# ATSAM4E16CB device description
Architecture: CORTEX-M4; Family: SAM4; Series: SAM4E
Registers are 32-bit, read-write, no defined reset value unless marked. A register's access mark holds for its fields unless they carry their own. Offsets are from the block's base; [hi:lo] are bit positions; {n}, {i} and the like mark numbered series.

## PIO — Parallel Input/Output Controller
Instances: PIOA 0x400E0E00, PIOB 0x400E1000, PIOC 0x400E1200
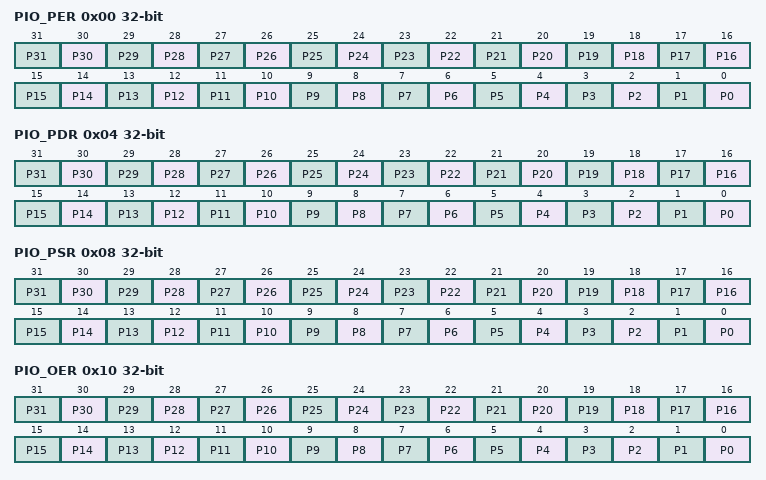
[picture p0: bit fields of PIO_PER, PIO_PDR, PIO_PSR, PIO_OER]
0x00 PIO_PER wo — PIO Enable Register
  [n] P{n} (n=0..31) — PIO Enable
0x04 PIO_PDR wo — PIO Disable Register
  [n] P{n} (n=0..31) — PIO Disable
0x08 PIO_PSR ro — PIO Status Register
  [n] P{n} (n=0..31) — PIO Status
0x10 PIO_OER wo — Output Enable Register
  [n] P{n} (n=0..31) — Output Enable
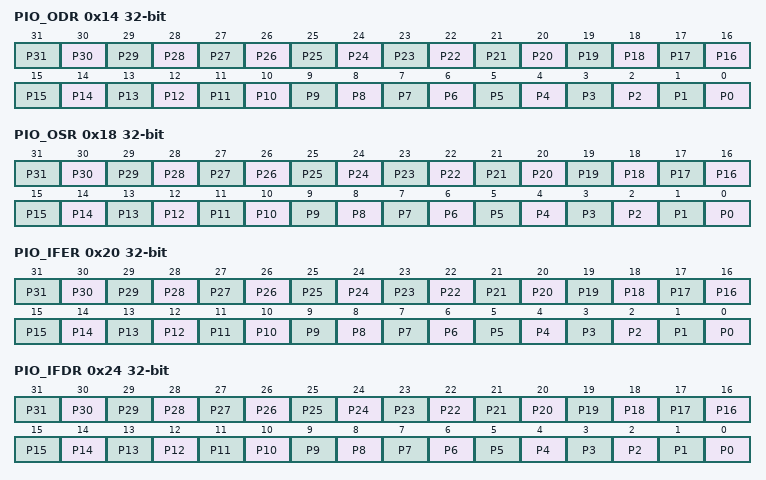
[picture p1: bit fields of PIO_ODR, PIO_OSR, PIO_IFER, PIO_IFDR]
0x14 PIO_ODR wo — Output Disable Register
  [n] P{n} (n=0..31) — Output Disable
0x18 PIO_OSR ro — Output Status Register
  [n] P{n} (n=0..31) — Output Status
0x20 PIO_IFER wo — Glitch Input Filter Enable Register
  [n] P{n} (n=0..31) — Input Filter Enable
0x24 PIO_IFDR wo — Glitch Input Filter Disable Register
  [n] P{n} (n=0..31) — Input Filter Disable
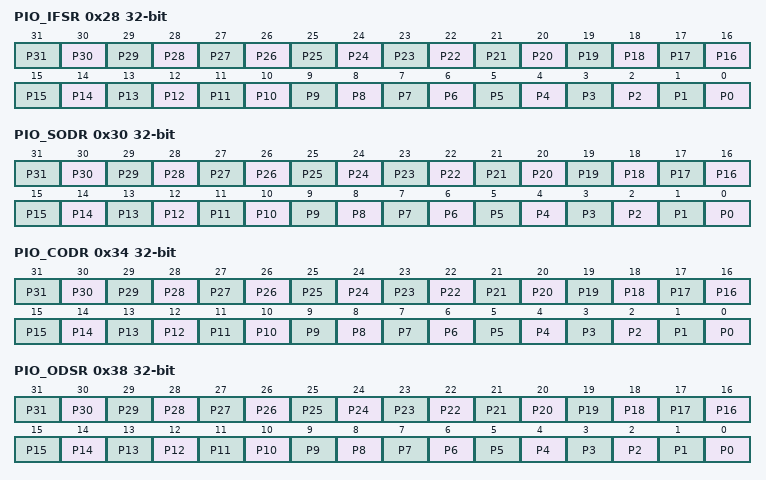
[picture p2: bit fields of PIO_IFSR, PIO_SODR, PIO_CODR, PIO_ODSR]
0x28 PIO_IFSR ro — Glitch Input Filter Status Register
  [n] P{n} (n=0..31) — Input Filer Status
0x30 PIO_SODR wo — Set Output Data Register
  [n] P{n} (n=0..31) — Set Output Data
0x34 PIO_CODR wo — Clear Output Data Register
  [n] P{n} (n=0..31) — Clear Output Data
0x38 PIO_ODSR — Output Data Status Register
  [n] P{n} (n=0..31) — Output Data Status
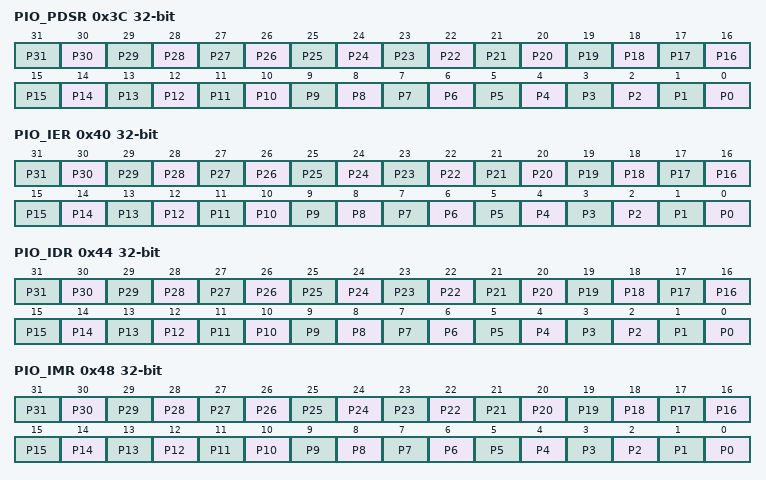
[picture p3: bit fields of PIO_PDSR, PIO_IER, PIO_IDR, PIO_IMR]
0x3C PIO_PDSR ro — Pin Data Status Register
  [n] P{n} (n=0..31) — Output Data Status
0x40 PIO_IER wo — Interrupt Enable Register
  [n] P{n} (n=0..31) — Input Change Interrupt Enable
0x44 PIO_IDR wo — Interrupt Disable Register
  [n] P{n} (n=0..31) — Input Change Interrupt Disable
0x48 PIO_IMR ro — Interrupt Mask Register
  [n] P{n} (n=0..31) — Input Change Interrupt Mask
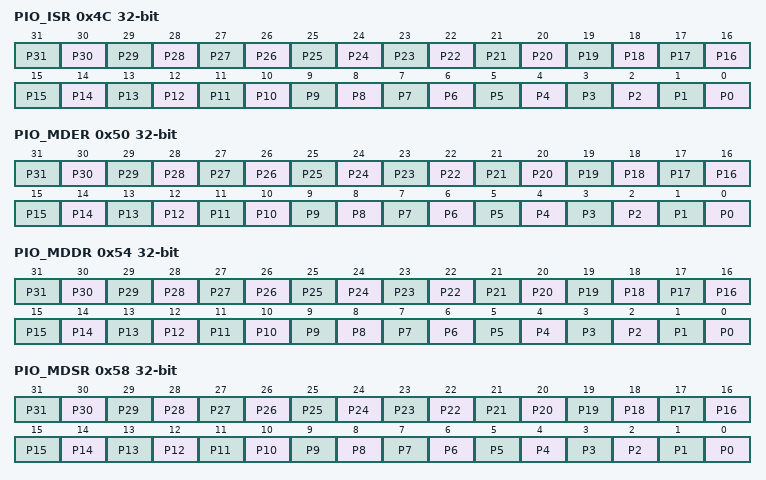
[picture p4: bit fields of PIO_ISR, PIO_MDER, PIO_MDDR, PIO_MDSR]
0x4C PIO_ISR ro — Interrupt Status Register
  [n] P{n} (n=0..31) — Input Change Interrupt Status
0x50 PIO_MDER wo — Multi-driver Enable Register
  [n] P{n} (n=0..31) — Multi-drive Enable
0x54 PIO_MDDR wo — Multi-driver Disable Register
  [n] P{n} (n=0..31) — Multi-drive Disable
0x58 PIO_MDSR ro — Multi-driver Status Register
  [n] P{n} (n=0..31) — Multi-drive Status
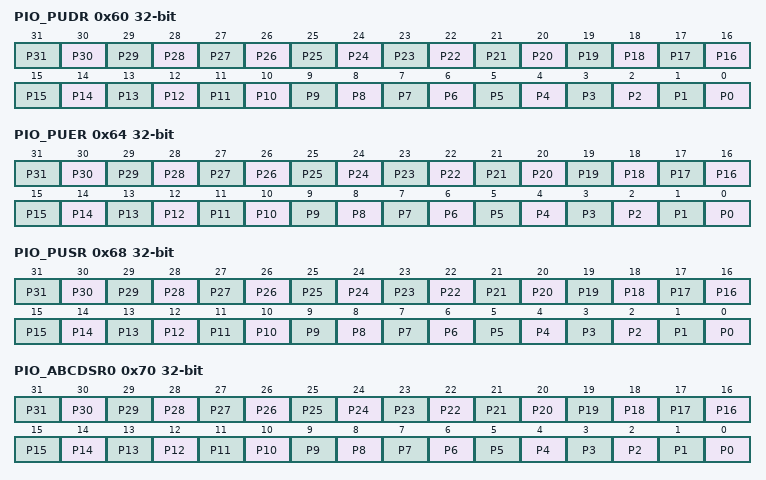
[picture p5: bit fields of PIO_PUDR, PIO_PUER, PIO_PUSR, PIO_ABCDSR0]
0x60 PIO_PUDR wo — Pull-up Disable Register
  [n] P{n} (n=0..31) — Pull-Up Disable
0x64 PIO_PUER wo — Pull-up Enable Register
  [n] P{n} (n=0..31) — Pull-Up Enable
0x68 PIO_PUSR ro — Pad Pull-up Status Register
  [n] P{n} (n=0..31) — Pull-Up Status
0x70 PIO_ABCDSR0 — Peripheral Select Register 0
  [n] P{n} (n=0..31) — Peripheral Select
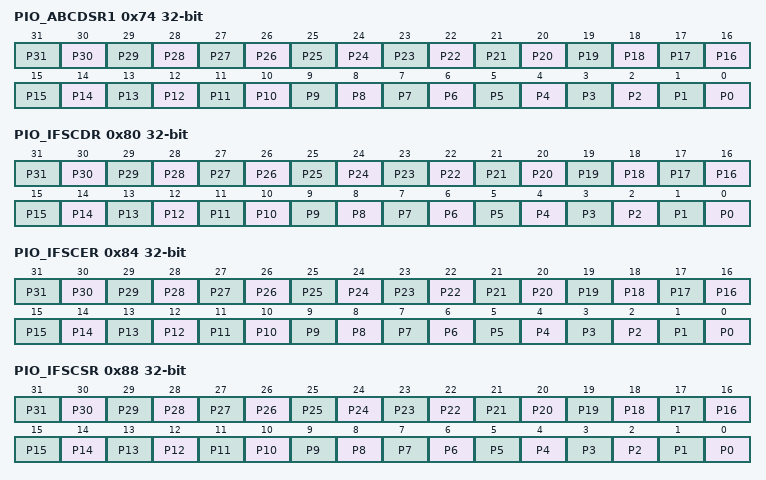
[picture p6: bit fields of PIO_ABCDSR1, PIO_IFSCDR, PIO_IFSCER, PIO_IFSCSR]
0x74 PIO_ABCDSR1 — Peripheral Select Register 1
  [n] P{n} (n=0..31) — Peripheral Select
0x80 PIO_IFSCDR wo — Input Filter Slow Clock Disable Register
  [n] P{n} (n=0..31) — Peripheral Clock Glitch Filtering Select
0x84 PIO_IFSCER wo — Input Filter Slow Clock Enable Register
  [n] P{n} (n=0..31) — Slow Clock Debouncing Filtering Select
0x88 PIO_IFSCSR ro — Input Filter Slow Clock Status Register
  [n] P{n} (n=0..31) — Glitch or Debouncing Filter Selection Status
0x8C PIO_SCDR — Slow Clock Divider Debouncing Register
  [13:0] DIV — Slow Clock Divider Selection for Debouncing
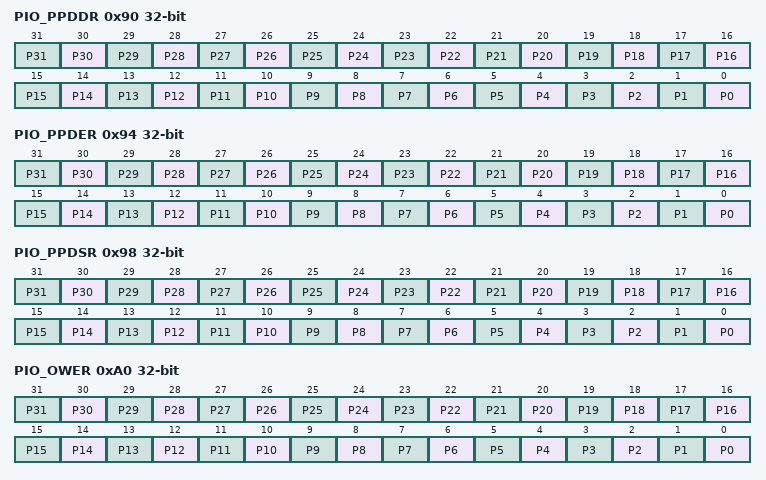
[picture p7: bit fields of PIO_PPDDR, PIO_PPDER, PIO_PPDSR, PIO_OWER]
0x90 PIO_PPDDR wo — Pad Pull-down Disable Register
  [n] P{n} (n=0..31) — Pull-Down Disable
0x94 PIO_PPDER wo — Pad Pull-down Enable Register
  [n] P{n} (n=0..31) — Pull-Down Enable
0x98 PIO_PPDSR ro — Pad Pull-down Status Register
  [n] P{n} (n=0..31) — Pull-Down Status
0xA0 PIO_OWER wo — Output Write Enable
  [n] P{n} (n=0..31) — Output Write Enable
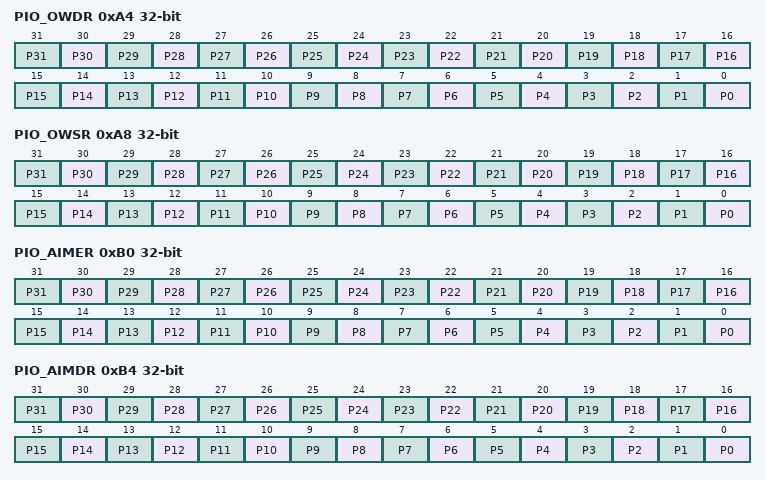
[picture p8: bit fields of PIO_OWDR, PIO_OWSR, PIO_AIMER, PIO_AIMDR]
0xA4 PIO_OWDR wo — Output Write Disable
  [n] P{n} (n=0..31) — Output Write Disable
0xA8 PIO_OWSR ro — Output Write Status Register
  [n] P{n} (n=0..31) — Output Write Status
0xB0 PIO_AIMER wo — Additional Interrupt Modes Enable Register
  [n] P{n} (n=0..31) — Additional Interrupt Modes Enable
0xB4 PIO_AIMDR wo — Additional Interrupt Modes Disable Register
  [n] P{n} (n=0..31) — Additional Interrupt Modes Disable
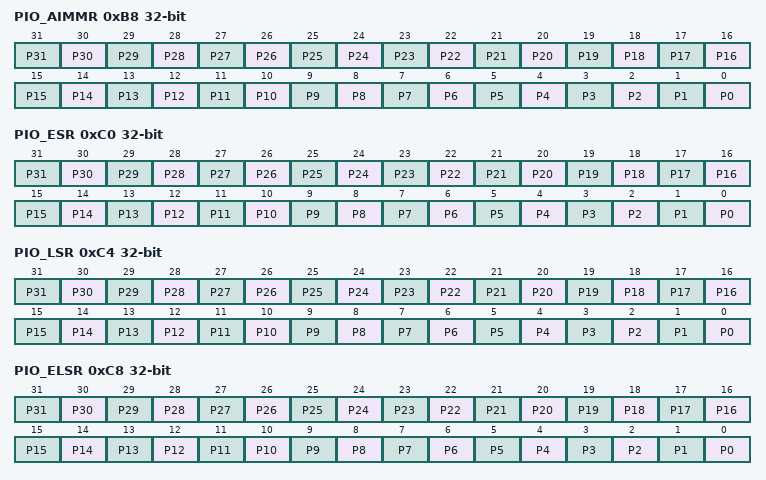
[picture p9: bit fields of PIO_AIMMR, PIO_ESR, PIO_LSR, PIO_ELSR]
0xB8 PIO_AIMMR ro — Additional Interrupt Modes Mask Register
  [n] P{n} (n=0..31) — Peripheral CD Status
0xC0 PIO_ESR wo — Edge Select Register
  [n] P{n} (n=0..31) — Edge Interrupt Selection
0xC4 PIO_LSR wo — Level Select Register
  [n] P{n} (n=0..31) — Level Interrupt Selection
0xC8 PIO_ELSR ro — Edge/Level Status Register
  [n] P{n} (n=0..31) — Edge/Level Interrupt Source Selection
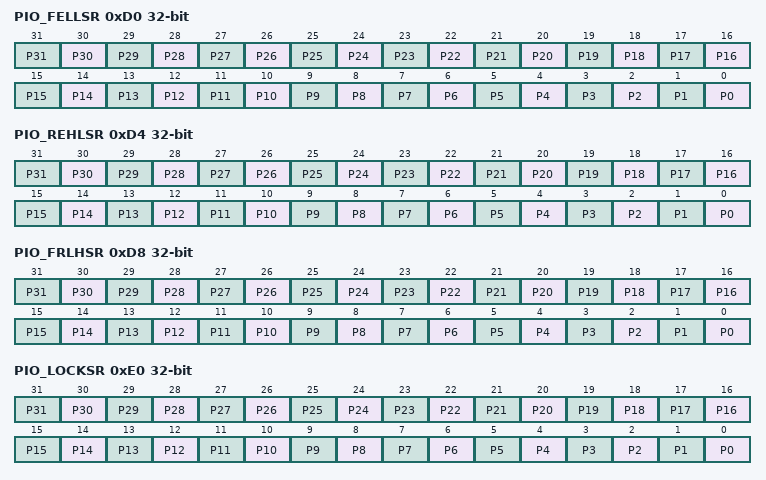
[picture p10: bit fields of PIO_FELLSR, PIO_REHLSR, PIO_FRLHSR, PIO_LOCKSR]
0xD0 PIO_FELLSR wo — Falling Edge/Low-Level Select Register
  [n] P{n} (n=0..31) — Falling Edge/Low-Level Interrupt Selection
0xD4 PIO_REHLSR wo — Rising Edge/High-Level Select Register
  [n] P{n} (n=0..31) — Rising Edge/High-Level Interrupt Selection
0xD8 PIO_FRLHSR ro — Fall/Rise - Low/High Status Register
  [n] P{n} (n=0..31) — Edge/Level Interrupt Source Selection
0xE0 PIO_LOCKSR ro — Lock Status
  [n] P{n} (n=0..31) — Lock Status
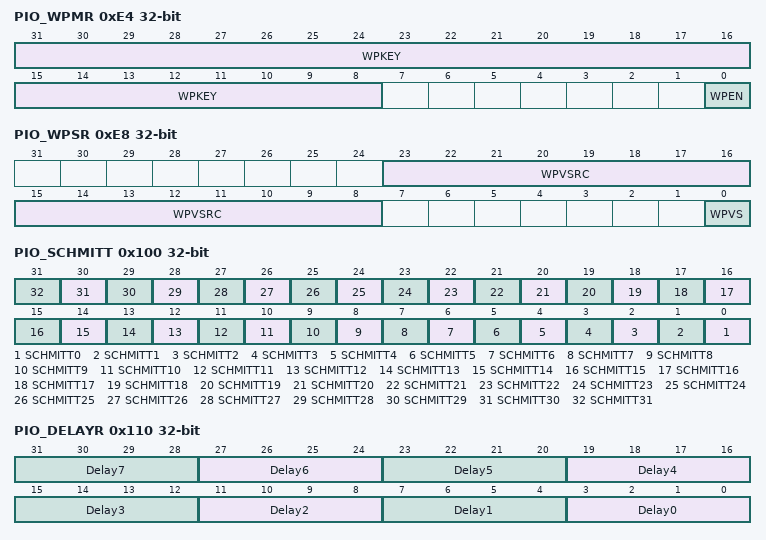
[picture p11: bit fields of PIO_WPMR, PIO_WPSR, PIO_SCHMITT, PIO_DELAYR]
0xE4 PIO_WPMR — Write Protection Mode Register
  [31:8] WPKEY — Write Protection Key
    0x50494F=PASSWD (Writing any other value in this field aborts the write operation of the WPEN bit. Always reads as 0.)
  [0] WPEN — Write Protection Enable
0xE8 PIO_WPSR ro — Write Protection Status Register
  [23:8] WPVSRC — Write Protection Violation Source
  [0] WPVS — Write Protection Violation Status
0x100 PIO_SCHMITT — Schmitt Trigger Register
  [n] SCHMITT{n} (n=0..31) — Schmitt Trigger Control
0x110 PIO_DELAYR — I/O Delay Register
  [4n+3:4n] Delay{n} (n=0..7) — Delay Control for Simultaneous Switch Reduction
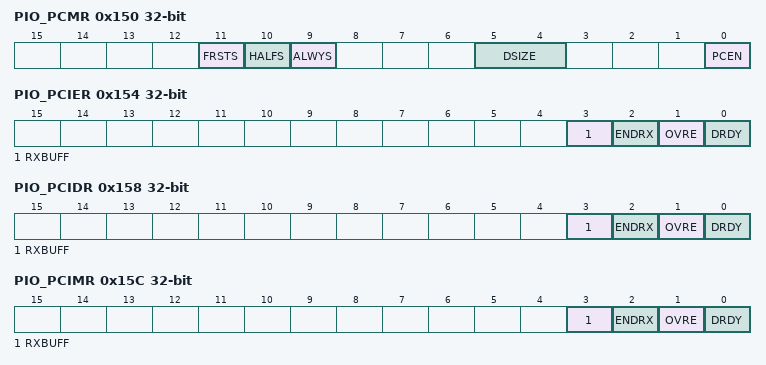
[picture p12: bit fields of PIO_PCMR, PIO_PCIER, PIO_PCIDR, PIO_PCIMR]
0x150 PIO_PCMR — Parallel Capture Mode Register
  [11] FRSTS — Parallel Capture Mode First Sample
  [10] HALFS — Parallel Capture Mode Half Sampling
  [9] ALWYS — Parallel Capture Mode Always Sampling
  [5:4] DSIZE — Parallel Capture Mode Data Size
    0=BYTE (The reception data in the PIO_PCRHR is a byte (8-bit)); 1=HALFWORD (The reception data in the PIO_PCRHR is a half-word (16-bit)); 2=WORD (The reception data in the PIO_PCRHR is a word (32-bit))
  [0] PCEN — Parallel Capture Mode Enable
0x154 PIO_PCIER wo — Parallel Capture Interrupt Enable Register
  [3] RXBUFF — Reception Buffer Full Interrupt Enable
  [2] ENDRX — End of Reception Transfer Interrupt Enable
  [1] OVRE — Parallel Capture Mode Overrun Error Interrupt Enable
  [0] DRDY — Parallel Capture Mode Data Ready Interrupt Enable
0x158 PIO_PCIDR wo — Parallel Capture Interrupt Disable Register
  [3] RXBUFF — Reception Buffer Full Interrupt Disable
  [2] ENDRX — End of Reception Transfer Interrupt Disable
  [1] OVRE — Parallel Capture Mode Overrun Error Interrupt Disable
  [0] DRDY — Parallel Capture Mode Data Ready Interrupt Disable
0x15C PIO_PCIMR ro — Parallel Capture Interrupt Mask Register
  [3] RXBUFF — Reception Buffer Full Interrupt Mask
  [2] ENDRX — End of Reception Transfer Interrupt Mask
  [1] OVRE — Parallel Capture Mode Overrun Error Interrupt Mask
  [0] DRDY — Parallel Capture Mode Data Ready Interrupt Mask
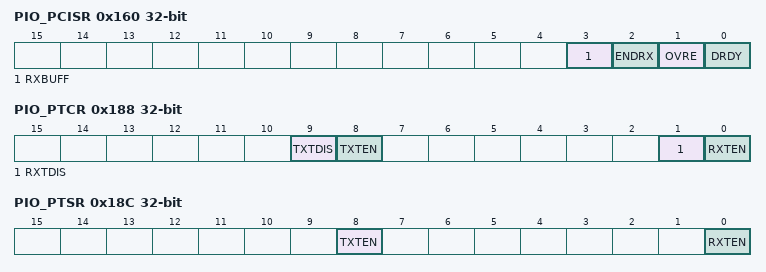
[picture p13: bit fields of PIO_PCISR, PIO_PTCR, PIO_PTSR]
0x160 PIO_PCISR ro — Parallel Capture Interrupt Status Register
  [3] RXBUFF — Reception Buffer Full
  [2] ENDRX — End of Reception Transfer.
  [1] OVRE — Parallel Capture Mode Overrun Error.
  [0] DRDY — Parallel Capture Mode Data Ready
0x164 PIO_PCRHR ro — Parallel Capture Reception Holding Register
  [31:0] RDATA — Parallel Capture Mode Reception Data.
0x168 PIO_RPR — Receive Pointer Register
  [31:0] RXPTR
0x16C PIO_RCR — Receive Counter Register
  [15:0] RXCTR
0x178 PIO_RNPR — Receive Next Pointer Register
  [31:0] RXNPTR — Receive Next Pointer
0x17C PIO_RNCR — Receive Next Counter Register
  [15:0] RXNCTR — Receive Next Counter
0x188 PIO_PTCR wo — Transfer Control Register
  [9] TXTDIS — Transmitter Transfer Disable
  [8] TXTEN — Transmitter Transfer Enable
  [1] RXTDIS — Receiver Transfer Disable
  [0] RXTEN — Receiver Transfer Enable
0x18C PIO_PTSR ro — Transfer Status Register
  [8] TXTEN — Transmitter Transfer Enable
  [0] RXTEN — Receiver Transfer Enable
